# 643x_cslr_psc_001 register map
Vendor: Texas Instruments
Peripheral module from a debugger description file.
Registers are 32-bit, read-only, reset 0x0 unless marked. A register's access mark holds for its fields unless they carry their own. Offsets are as the file gives them; lines under a group give offsets from that group; [hi:lo] are bit positions; {n}, {i} and the like mark numbered series; 'fields as' and 'values as' point back to an identical list; <NAME> marks a mode.

## PSC — Power and Sleep Controller (PSC) Version 0.95
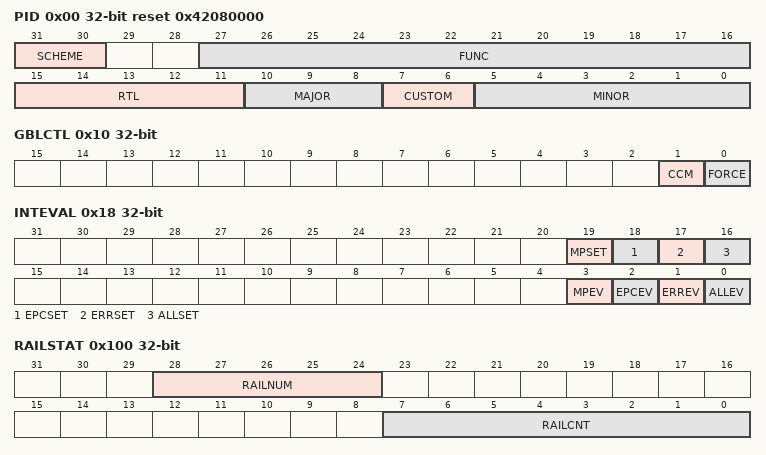
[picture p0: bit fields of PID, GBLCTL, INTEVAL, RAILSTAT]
0x00 PID reset 0x42080000 — Peripheral Revision and Class Information
  [31:30] SCHEME — Used to distinguish between old scheme and current. Spare bit to encode future schemes
  [27:16] FUNC — Indicating a software compatible module family. If there is no level of software compatibility a new ID should be assigned.
  [15:11] RTL — RTL Version. (R as described in PDR 9.3.2) Must be easily ECO'able or controlled during fabrication. Ideally through a top level metal mask or efuse. Start with 0 for PSC1.0, 1 for PSC2.0
  [10:8] MAJOR — Major Revision.
  [7:6] CUSTOM — Indicates a Special Version for a particular device. Consequence of use may avoid use of standard CSL/Drivers. 0 if non-custom
  [5:0] MINOR — Minor Revision Must be easily ECO'able or controlled during fabrication. Ideally through a top level metal mask or efuse. Start with 0.
0x10 GBLCTL access per field — Global Control Register
  [1] CCM rw — PSC MMR controlled by Chip Config Module (CCM) only 0: Software is allowed to control PSC 1: PSC is controlled by CCM
  [0] FORCE rw — Force bit. For PSC 2.0, this bit is considered only if all of the conditions are true: -GBLCTL.CCM = 0 -Software manual control method is used 0: No force 1: Force
0x14 GBLSTAT — Global Status Register
  [0] GBLTRANS — PSC Global Transition Status 0: No Global Transition in progress 1: Global Transition in progress. PSC hardware is in the process of putting all power domains to the desired next states, and all modules to the desired next states
0x18 INTEVAL access per field — Interrupt Evaluation Register
  [19] MPSET wo — Memory Protection Interrupt Set 0: Write of 0 has no effect 1: Write of 1 causes the PSC_MPINT to be pulsed.
  [18] EPCSET wo — External Power Control Interrupt Set (not documented to users) 0: Write of 0 has no effect 1: Write of 1 causes the PSC_EPCINT to be pulsed
  [17] ERRSET wo — Error Interrupt Set (not documented for users) 0: Write of 0 has no effect 1: Write of 1 causes the PSC_ERRINT to be pulsed
  [16] ALLSET wo — Combined Interrupt Set (not documented to users) 0: Write of 0 has no effect 1: Write of 1 causes the PSC_ALLINT to be pulsed
  [3] MPEV wo — Re-evaluate Memory Protection Interrupt 0: Write of 0 has no effect 1: Write of 1 re-evaluate memory protection interrupt PSC_MPINT
  [2] EPCEV wo — External Power Control Interrupt Set 0: Write of 0 has no effect 1: Write of 1 re-evaluate external power control interrupt PSC_EPCINT
  [1] ERREV wo — Re-evaluate Error Interrupt 0: Write of 0 has no effect 1: Write of 1 re-evaluate error Interrupt PSC_ERRINT
  [0] ALLEV wo — Re-evaluate combined PSC interrupt 0: Write of 0 has no effect 1: Write of 1 re-evaluate the combined PSC interrupt PSC_ALLINT
0x40 MERRPR0 — Module Error Pending 0 (mod 0 - 31) Register
  [31:0] M[32] — Records pending error conditions for modules 0-31. Each bit n respresents a module. For each bit n, 0: Module n does not have error condition 1: Module n has error condition
0x44 MERRPR1 — Module Error Pending 1 (mod 32 - 63) Register
  [31:0] M[32] — Records pending error conditions for modules 32-63. Each bit n respresents a module. For each bit n, 0: Module n does not have error condition 1: Module n has error condition
0x50 MERRCR0 wo — Module Error Clear 0 (mod 0-31) Register
  [31:0] M[32] — Clears error bit set in corresponding ERRPR register bit field. This pertains to modules 0-31. For each bit n, 0: Write of 0 has no effect 1: Write of 1 to bit n causes ERRPR bit n to be cleared, and the corresponding module's MDSTAT fields to be cleared - STERR, WKRSLP, ACSLP, MSTID.
0x54 MERRCR1 wo — Module Error Clear 1 (mod 32-63) Register
  [31:0] M[32] — Clears error bit set in corresponding ERRPR register bit field. This pertains to modules 32-63. For each bit n, 0: Write of 0 has no effect 1: Write of 1 to bit n causes ERRPR bit n to be cleared, and the corresponding module's MDSTAT fields to be cleared - STERR, WKRSLP, ACSLP, MSTID.
0x60 PERRPR — Power Error Pending Register
  [31:0] P[32] — Power Domain n Error Condition 0: Power domain n does not have error condition 1: Power domain n has error condition
0x68 PERRCR wo — Power Error Clear Register
  [31:0] P[32] — 0: Write of 0 has no effect 1: Write of 1 clears the corresponding PERRPR bit
0x70 EPCPR — Power Error Pending Register
  [31:0] EPC[32] — External Power Control Intervention Request for Power Domain n 0: No need for external power control to turn on/off power for Power Doamin n 1: External Power Control intervention is needed for turning on/off power for Power domain n
0x78 EPCCR wo — External Power Control Clear Register
  [31:0] EPC[32] — 0: Write of 0 has no effect 1: Write of 1 clears the corresponding EPCPR bit
0x100 RAILSTAT — Power Rail Status Register
  [28:24] RAILNUM — Indicates Current Rail Requestor being processed by GPSC. Defaults to 0 indicating Always ON domain that has no rail request/grant associated with it. The 5 bit field allows up to 32 requestors.
  [7:0] RAILCNT — Indicates the current rail counter value. This is a dynamic field and reading this will not reflect real-time value.
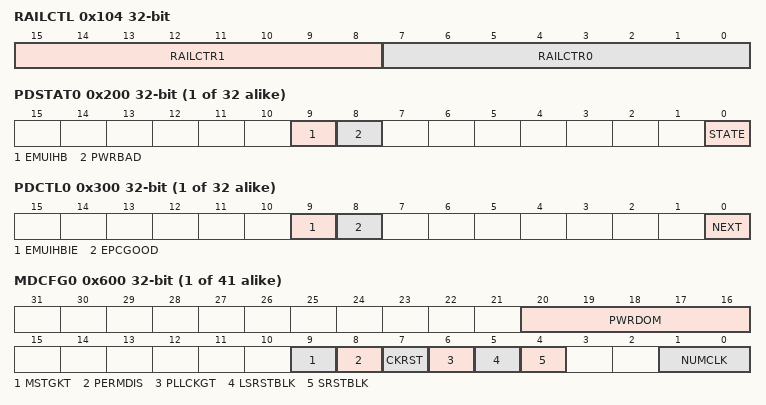
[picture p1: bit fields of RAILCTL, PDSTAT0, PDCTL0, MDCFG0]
0x104 RAILCTL access per field — Power Rail Counter Control Register
  [15:8] RAILCTR1 rw — Rail Counter Value 1
  [7:0] RAILCTR0 rw — Rail Counter Value 0
0x108 RAILSEL rw — Power Rail Counter Select Register
  [31:0] P[32] — Rail Counter Select for Power Domain n 0: Use RAILCTL.RailCtr0 count value to bring up power domain n 1: Use RAILCTL.RailCtr1 count value to bring up power domain n
0x120 PTCMD rw — Power Domain Transition Command Register
  [31:0] GO[32] — PSC 1.0 definition: Power Domain n Evaluation 0: Writes of 0 has no effect 1: Writes of 1 cause the State Transition Interrupt Generation Block to evaluate the new PTNEXT and MDCTL.NEXT states as the Application desired states. PSC 2.0 definition: Power Domain n GO Transition 0: Writes of 0 have no effect 1: Writes of 1 cause PSC hardware to evaluate PTNEXT and MDCTL.NEXT (for this domain).
0x128 PTSTAT — Power Domain Transition Status Register
  [31:0] GOSTAT[32] — Power Domain n Transition Command Status, where n ranges from 31 down to 0 0: No transitions in progress in Power Domain n 1: Power Domain 0 Transition in progress - either the power domain is transitioning, or modules on this domain are transitioning. Note: Power domain 0 is reserved for the Always ON domain, this bit is always 0.
{0x200+4i} PDSTAT{i} (i=0..31) — Power Domain Status {i} Register
  [9] EMUIHB — Emulation Alters Domain State - Inhibits Off or Forces ON 0: No emulation altering user-desired power domain state 1: Emulation alters user-desired power state
  [8] PWRBAD — Power Bad error. The power domain is in ON or WASRD state, but pwr_good_pi input is de-asserted to indicate power bad. 0: No error 1: Error detected
  [0] STATE — Current Power Domain State 0: Off 1: On
{0x300+4i} PDCTL{i} access per field (i=0..31) — Power Domain Control {i} Register
  [9] EMUIHBIE rw — Emulation alters domain state (Inhibits domain Off or Forces Domain On) Interrupt Enable 0: Not enabled 1: Enabled
  [8] EPCGOOD rw — External Power Control Power Good Indication. 0: External Power Control has turned off power to this domain 1: External Power Control has turned on power to this domain and the power has reached a desired threshold.
  [0] NEXT rw — User-Desired Next Power Domain State 0: Off 1: On
0x500 MRSTOUT0 — Module Reset Output (mod 0-31) Register
  [31:0] MRSTz[32] — For Module 31 down-to 0, actual modrstz output to module 0: modrstz asserted 1: modrstz not asserted
0x504 MRSTOUT1 — Module Reset Output (mod 32-63) Register
  [31:0] MRSTz[32] — For Module 63 down-to 32, actual modrstz output to module 0: modrstz asserted 1: modrstz not asserted
0x510 MCKOUT0 — Module Clock Output Status (mod 0-31) Register
  [31:0] MCK[32] — For Module 31 down-to 1, actual modclk output to module 0: modclk gated 1: modclk on
0x514 MCKOUT1 — Module Clock Output Status (mod 32-63) Register
  [31:0] MCK[32] — For Module 63 down-to 32, actual modclk output to module 0: modclk gated 1: modclk on
{0x600+4i} MDCFG{i} (i=0..40) — Module Configuration {i} Register
  [20:16] PWRDOM — Power Domain Indicates which power domain this module belongs to (0 to 31)
  [9] MSTGKT — Master Gasket support. Reflects the RTL parameter MSTGKT 0: Master Gasket not supported by LPSC 1: Master Gasket supported by LPSC
  [8] PERMDIS — Permanently Disable Not documented to users 0: Not permanently disable module 1: Permamanently disable module
  [7] CKRST — Modclk During MSM reset source assert. Shows the tieoff d_mdcfg[x]_clk_during_hard_rst_src. MSM reset source is either hard_rst_src_assert_pi_n or any_rst_src_assert_pi_n 0: LPSC does not give modclk when its MSM reset source is asserted. LPSC only gives modclk after the MSM reset source is de-asserted 1: LPSC gives modclk even when the MSM reset source is asserted
  [6] PLLCKGT — PLL Clock gate. Shows the tieoff d_mdcfg[x]_pll_handshake 0: LPSC gates modclk directly 1: LPSC does not gate modclk directly. LPSC instructs the PLLCTRL to gate modclk.
  [5] LSRSTBLK — LRST Soft Reset Block. Shows the tieoff d_mdcfg[x]_lrst_soft_rst_block value. 0: Soft resets are not blocked to LRST. 1: Soft resets are blocked to LRST.
  [4] SRSTBLK — Soft Reset Block. Shows the tieoff d_mdcfg[x]_soft_rst_block value. 0: Soft resets are not blocked. Any grstz from PLLCTRL will be propagated to the module 1: Soft resets are blocked LPSC only passes hard resets to the module
  [1:0] NUMCLK — Number of modclks supported on LPSC 0: 1 modclk 1: 2 modclks 2: 3 modclks 3: 4 modclks
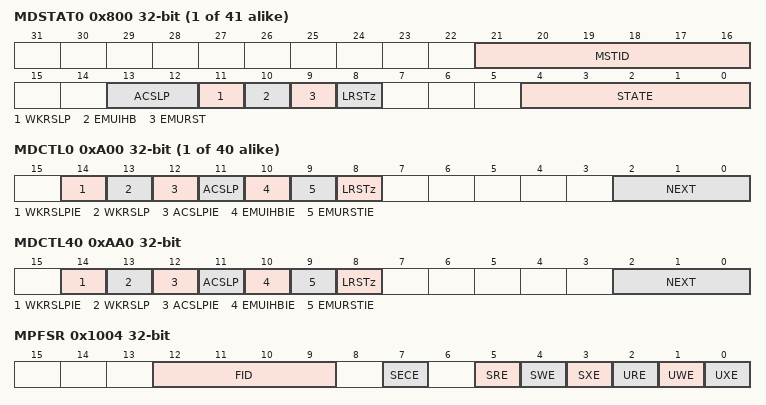
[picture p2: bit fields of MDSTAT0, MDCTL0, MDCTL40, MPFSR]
{0x800+4i} MDSTAT{i} (i=0..40) — Module Status {i} Register
  [21:16] MSTID — Master ID. If ACSLP occurs, this field records the master ID of the master that caused the access. This bit is cleared when the corresponding ERRCR bit is written with a 1.
  [13:12] ACSLP — Non-emulation access to Module in Sleep occurred. 00: Condition did not occur 01: Access to module in sleep occurred. PSC transitioned the module from Sleep state to Temp Wake state then back to Sleep state 10: Access to module in sleep occured. PSC transitioned the module from Sleep state to Enable state 11: Reserved
  [11] WKRSLP — Wakeup Request to Module in Sleep Detected. Wakeup_pi is detected for this module when it is in sleep. If MDCTL.WKRSLPIE = 1, the setting of this field can cause ERRPR for this module to be set. 0: Condition did not occur 1: wakeup_pi = 1 when module is in sleep.
  [10] EMUIHB — Emulation Alters Module State - Inhibits Module Inactive or Force Module Active 0: No emulation altering user-desired module state 1: Emulation alters user-desired module state
  [9] EMURST — Emulation Alters Reset (lrst or mrst) to Module 0: No emulation altering user-desired reset 1: Emulation alters user-desired module state
  [8] LRSTz — Module local reset actual status 0: local reset asserted 1: local reset de-asserted
  [4:0] STATE — These bits indiacte the current module state 010: SyncReset 000: SwRstDisable 001: Disable 011: Enable 111: Disable Clock-On Transition 100, 101, 110: Reserved
{0xA00+4i} MDCTL{i} access per field (i=0..39) — Module Control {i} Register
  [14] WKRSLPIE rw — Wakeup Request to module in sleep Error Enable. 0: Wakeup request to module in sleep is not considered an error condition 1: Wakeup request to module in sleep is considered an error
  [13] WKRSLP rw — Wakeup Request to module in Sleep will cause this action. 0: PSC transitions module from Sleep state to TWK state, once access completes (vbus_req = 0) put module back in Sleep state 1: PSC transitions module to ENABLE state
  [12] ACSLPIE rw — Non-emulation Access to module in sleep Error enable 0: Non-emulation access to module in sleep is not considered an error condition 1: Non-emulation access to module in sleep is considered an error
  [11] ACSLP rw — Non-emulation Access to module in Sleep will cause this action 0: PSC transitions module from Sleep state to TWk state, once access completes put module back in Sleep state 1: PSC transitions module to ENABLE state
  [10] EMUIHBIE rw — Emulation alters module state - Inhibits Module Inactive or Force Module Active 0: Not enabled 1: Interrupt enabled
  [9] EMURSTIE rw — Emulation Alter Reset Interrupt Enable 0: Not enabled 1: Interrupt Enabled
  [8] LRSTz rw — Module local reset control (only applicable to some modules -- e.g GEM, BCG EMIF) 0: Assert local reset 1: De-assert local reset
  [2:0] NEXT rw — Module Next State 000: SwRstDisable 001: Disable 010: SyncReset 011: Enable 100: Reserved/Invalid 101: Sleep 110: Reserved/Invalid 111: Reserved/Invalid
0xAA0 MDCTL40 access per field — Module Control 30 Register
  fields as MDCTL0
0x1000 MPFAR — Memory Protection Fault Address Register
  [31:0] FADDR — Memory Protection Fault Address Captures the faulting address when a memory protection vioaltion is detected. This register can only be cleared via MPFCR.MPFCLR
0x1004 MPFSR access per field — Memory Protection Fault Status Register
  [12:9] FID ro — Faulted ID FID contains valid info if any of the MP error bits (UXE, UWE, URE, SXE, SWE, SRE) are non-zero. The FID field contains the vbus PrivID for the specific request/requestor that resulted in a MP error.
  [7] SECE ro — Secure Access Error Hard-wired to 0 to show no secure access error - because PSC does not check for security.
  [5] SRE ro — Supervisor Read Error SRE = 0: No error detected SRE = 1: Supervisor level task attempted to read from a MP page without SR permissions
  [4] SWE ro — Supervisor Write Error SWE = 0: No error detected SWE = 1: Supervisor level task attempted to write to a MP page without SW permissions
  [3] SXE ro — Supervisor Execute Error. This bit is hard-wired to 0 to indicate no Supervisor Execute Error (because PSC does not check for VBUS data type vbus_dtype)
  [2] URE ro — User Read Error URE = 0: No Error detected URE = 1: User level task attempted to read from a MP page without UR permissions
  [1] UWE ro — User Write Error UWE = 0: No error detected UWE = 1: User level task attempted to write to a MP page without UW permissions
  [0] UXE ro — User Execute Error. This bit is hard-wired to 0 to indicate no User Execute Error (because PSC does not check for VBUS data type vbus_dtype)
0x1008 MPFCR access per field — Memory Protection Fault Command Register
  [0] MPFCLR wo — Fault Clear Write of 1 to this bit causes any error conditions stored in MPFAR and MPFSR registers to be cleared. Write of 0 has no effect
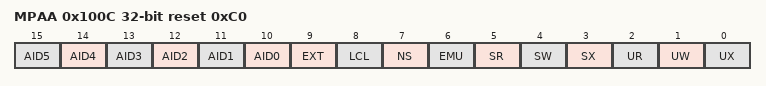
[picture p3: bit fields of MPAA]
0x100C MPAA access per field reset 0xC0 — Memory Protection Page Attribute Register
  [n+10] AID{n} rw (n=0..5) — Allowed ID {n} AID{n} = 0: VBUS requests with PrivID == {n} are not allowed to this MMR region regardless of permission settings (UW, UR, SW, SR) AID{n} = 1: VBUS requests with PrivID == {n} are permitted if access type is allowed as defined by permission settings (UW, UR, SW, SR)
  [9] EXT rw — External Allowed ID EXT = 0: VBUS requests with PrivID >= 6 are not allowed to this MMR region regardless of permission settings (UW, UR, SW, SR) EXT = 1: VBUS requests with PrivID >= 6 are permitted if access type is allowed as defined by permission settings (UW, UR, SW, SR)
  [8] LCL ro — Local access permission (Not applicable) Local accesses are not applicable, therefore hard-code this value to 0
  [7] NS ro — Secure Access Permission (not applicable) Hard-wired to 1 to show page is not secure. Secure and non-secure code can both access this MMR region.
  [6] EMU ro — Emulation Security Permission (not applicable) Hard-wired to 1 to indicate emulation read/write to this page is permitted.
  [5] SR rw — Supervisor Read Permission UR = 0: Supervisor reads are not allowed to this MMR region UR = 1: Supervisor reads allowed to this MMR region
  [4] SW rw — Supervisor Write Permission UW = 0: Supervisor writes are not allowed to this MMR region UW = 1: Supervisor writes allowed to this MMR region
  [3] SX ro — Supervisor Execute Permission (not applicable) This bit is hard-wired to 0 to indicate no Supervisor Execute Permission (because PSC does not check for VBUS data type vbus_dtype)
  [2] UR rw — User Read Permission UR = 0: User reads not allowed to this MMR region UR = 1: User reads allowed to this MMR region
  [1] UW rw — User Write Permission UW = 0: User writesnot allowed to this MMR region UW = 1: User writes allowed to this MMR region
  [0] UX ro — User Execute Permission (not applicable) This bit is hard-wired to 0 to indicate no User Execute Permission (because PSC does not check for VBUS data type vbus_dtype)
